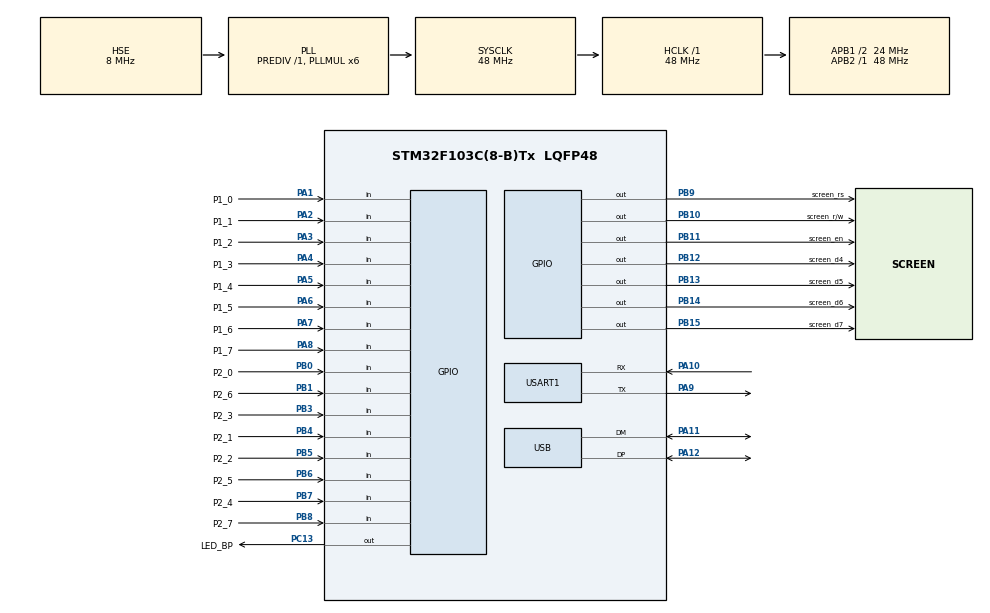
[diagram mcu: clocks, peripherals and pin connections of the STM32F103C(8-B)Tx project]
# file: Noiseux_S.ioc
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Mcu.Family=STM32F1
Mcu.Name=STM32F103C(8-B)Tx
Mcu.Package=LQFP48
NVIC.PriorityGroup=NVIC_PRIORITYGROUP_4
NVIC.USB_LP_CAN1_RX0_IRQn=true\:0\:0\:false\:false\:true\:false\:true\:true
PA1.GPIO_Label=P1_0
PA1.Signal=GPIO_Input
PA10.Mode=Asynchronous
PA10.Signal=USART1_RX
PA11.Mode=Device
PA11.Signal=USB_DM
PA12.Mode=Device
PA12.Signal=USB_DP
PA2.GPIO_Label=P1_1
PA2.Signal=GPIO_Input
PA3.GPIO_Label=P1_2
PA3.Signal=GPIO_Input
PA4.GPIO_Label=P1_3
PA4.Signal=GPIO_Input
PA5.GPIO_Label=P1_4
PA5.Signal=GPIO_Input
PA6.GPIO_Label=P1_5
PA6.Signal=GPIO_Input
PA7.GPIO_Label=P1_6
PA7.Signal=GPIO_Input
PA8.GPIO_Label=P1_7
PA8.Signal=GPIO_Input
PA9.Mode=Asynchronous
PA9.Signal=USART1_TX
PB0.GPIO_Label=P2_0
PB0.Signal=GPIO_Input
PB1.GPIO_Label=P2_6
PB1.Signal=GPIO_Input
PB10.GPIO_Label=screen_r/w
PB10.Signal=GPIO_Output
PB11.GPIO_Label=screen_en
PB11.Signal=GPIO_Output
PB12.GPIO_Label=screen_d4
PB12.Signal=GPIO_Output
PB13.GPIO_Label=screen_d5
PB13.Signal=GPIO_Output
PB14.GPIO_Label=screen_d6
PB14.Signal=GPIO_Output
PB15.GPIO_Label=screen_d7
PB15.Signal=GPIO_Output
PB3.GPIO_Label=P2_3
PB3.Signal=GPIO_Input
PB4.GPIO_Label=P2_1
PB4.Signal=GPIO_Input
PB5.GPIO_Label=P2_2
PB5.Signal=GPIO_Input
PB6.GPIO_Label=P2_5
PB6.Signal=GPIO_Input
PB7.GPIO_Label=P2_4
PB7.Signal=GPIO_Input
PB8.GPIO_Label=P2_7
PB8.Signal=GPIO_Input
PB9.GPIO_Label=screen_rs
PB9.Signal=GPIO_Output
PC13-TAMPER-RTC.GPIO_Label=LED_BP
PC13-TAMPER-RTC.Signal=GPIO_Output
PD0-OSC_IN.Mode=HSE-External-Oscillator
PD0-OSC_IN.Signal=RCC_OSC_IN
PD1-OSC_OUT.Mode=HSE-External-Oscillator
PD1-OSC_OUT.Signal=RCC_OSC_OUT
ProjectManager.HeapSize=0x200
ProjectManager.StackSize=0x400
ProjectManager.TargetToolchain=STM32CubeIDE
RCC.AHBFreq_Value=48000000
RCC.APB1CLKDivider=RCC_HCLK_DIV2
RCC.APB1Freq_Value=24000000
RCC.APB1TimFreq_Value=48000000
RCC.APB2Freq_Value=48000000
RCC.APB2TimFreq_Value=48000000
RCC.HCLKFreq_Value=48000000
RCC.PLLMUL=RCC_PLL_MUL6
RCC.SYSCLKFreq_VALUE=48000000
RCC.SYSCLKSource=RCC_SYSCLKSOURCE_PLLCLK
RCC.USBFreq_Value=48000000
USART1.VirtualMode=VM_ASYNC
USB_DEVICE.CLASS_NAME_FS=CDC
USB_DEVICE.VirtualMode=Cdc
USB_DEVICE.VirtualModeFS=Cdc_FS
VP_SYS_VS_ND.Mode=No_Debug
VP_USB_DEVICE_VS_USB_DEVICE_CDC_FS.Mode=CDC_FS
board=custom

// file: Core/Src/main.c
/* USER CODE BEGIN Header */
/**
  ******************************************************************************
  * @file           : main.c
  * @brief          : Main program body
  ******************************************************************************
  * @attention
  *
  * Copyright (c) 2025 STMicroelectronics.
  * All rights reserved.
  *
  * This software is licensed under terms that can be found in the LICENSE file
  * in the root directory of this software component.
  * If no LICENSE file comes with this software, it is provided AS-IS.
  *
  ******************************************************************************
  */
/* USER CODE END Header */
#include "main.h"
#include "usb_device.h"

/* USER CODE BEGIN Includes */
#include "usbd_cdc_if.h"
#include "ecran.h"

/* USER CODE END Includes */

UART_HandleTypeDef huart1;

void SystemClock_Config(void);
static void MX_GPIO_Init(void);
static void MX_USART1_UART_Init(void);

int main(void)
{

  /* MCU Configuration--------------------------------------------------------*/

  /* Reset of all peripherals, Initializes the Flash interface and the Systick. */
  HAL_Init();

  /* Configure the system clock */
  SystemClock_Config();

  /* Initialize all configured peripherals */
  MX_GPIO_Init();
  MX_USART1_UART_Init();
  MX_USB_DEVICE_Init();
  /* USER CODE BEGIN 2 */
  LCD_Init();

  /* USER CODE END 2 */

  /* Infinite loop */
  /* USER CODE BEGIN WHILE */
  while (1)
  {
	  LCD_Char(0x00);
    /* USER CODE END WHILE */

  }
}

void SystemClock_Config(void)
{
  RCC_OscInitTypeDef RCC_OscInitStruct = {0};
  RCC_ClkInitTypeDef RCC_ClkInitStruct = {0};
  RCC_PeriphCLKInitTypeDef PeriphClkInit = {0};

  /** Initializes the RCC Oscillators according to the specified parameters
  * in the RCC_OscInitTypeDef structure.
  */
  RCC_OscInitStruct.OscillatorType = RCC_OSCILLATORTYPE_HSE;
  RCC_OscInitStruct.HSEState = RCC_HSE_ON;
  RCC_OscInitStruct.HSEPredivValue = RCC_HSE_PREDIV_DIV1;
  RCC_OscInitStruct.HSIState = RCC_HSI_ON;
  RCC_OscInitStruct.PLL.PLLState = RCC_PLL_ON;
  RCC_OscInitStruct.PLL.PLLSource = RCC_PLLSOURCE_HSE;
  RCC_OscInitStruct.PLL.PLLMUL = RCC_PLL_MUL6;
  if (HAL_RCC_OscConfig(&RCC_OscInitStruct) != HAL_OK)
  {
    Error_Handler();
  }

  /** Initializes the CPU, AHB and APB buses clocks
  */
  RCC_ClkInitStruct.ClockType = RCC_CLOCKTYPE_HCLK|RCC_CLOCKTYPE_SYSCLK
                              |RCC_CLOCKTYPE_PCLK1|RCC_CLOCKTYPE_PCLK2;
  RCC_ClkInitStruct.SYSCLKSource = RCC_SYSCLKSOURCE_PLLCLK;
  RCC_ClkInitStruct.AHBCLKDivider = RCC_SYSCLK_DIV1;
  RCC_ClkInitStruct.APB1CLKDivider = RCC_HCLK_DIV2;
  RCC_ClkInitStruct.APB2CLKDivider = RCC_HCLK_DIV1;

  if (HAL_RCC_ClockConfig(&RCC_ClkInitStruct, FLASH_LATENCY_1) != HAL_OK)
  {
    Error_Handler();
  }
  PeriphClkInit.PeriphClockSelection = RCC_PERIPHCLK_USB;
  PeriphClkInit.UsbClockSelection = RCC_USBCLKSOURCE_PLL;
  if (HAL_RCCEx_PeriphCLKConfig(&PeriphClkInit) != HAL_OK)
  {
    Error_Handler();
  }
}

static void MX_USART1_UART_Init(void)
{

  huart1.Instance = USART1;
  huart1.Init.BaudRate = 115200;
  huart1.Init.WordLength = UART_WORDLENGTH_8B;
  huart1.Init.StopBits = UART_STOPBITS_1;
  huart1.Init.Parity = UART_PARITY_NONE;
  huart1.Init.Mode = UART_MODE_TX_RX;
  huart1.Init.HwFlowCtl = UART_HWCONTROL_NONE;
  huart1.Init.OverSampling = UART_OVERSAMPLING_16;
  if (HAL_UART_Init(&huart1) != HAL_OK)
  {
    Error_Handler();
  }

}

static void MX_GPIO_Init(void)
{
  GPIO_InitTypeDef GPIO_InitStruct = {0};

  /* GPIO Ports Clock Enable */
  __HAL_RCC_GPIOC_CLK_ENABLE();
  __HAL_RCC_GPIOD_CLK_ENABLE();
  __HAL_RCC_GPIOA_CLK_ENABLE();
  __HAL_RCC_GPIOB_CLK_ENABLE();

  /*Configure GPIO pin Output Level */
  HAL_GPIO_WritePin(LED_BP_GPIO_Port, LED_BP_Pin, GPIO_PIN_RESET);

  /*Configure GPIO pin Output Level */
  HAL_GPIO_WritePin(GPIOB, screen_r_w_Pin|screen_en_Pin|screen_d4_Pin|screen_d5_Pin
                          |screen_d6_Pin|screen_d7_Pin|screen_rs_Pin, GPIO_PIN_RESET);

  /*Configure GPIO pin : LED_BP_Pin */
  GPIO_InitStruct.Pin = LED_BP_Pin;
  GPIO_InitStruct.Mode = GPIO_MODE_OUTPUT_PP;
  GPIO_InitStruct.Pull = GPIO_NOPULL;
  GPIO_InitStruct.Speed = GPIO_SPEED_FREQ_LOW;
  HAL_GPIO_Init(LED_BP_GPIO_Port, &GPIO_InitStruct);

  /*Configure GPIO pins : P1_0_Pin P1_1_Pin P1_2_Pin P1_3_Pin
                           P1_4_Pin P1_5_Pin P1_6_Pin P1_7_Pin */
  GPIO_InitStruct.Pin = P1_0_Pin|P1_1_Pin|P1_2_Pin|P1_3_Pin
                          |P1_4_Pin|P1_5_Pin|P1_6_Pin|P1_7_Pin;
  GPIO_InitStruct.Mode = GPIO_MODE_INPUT;
  GPIO_InitStruct.Pull = GPIO_NOPULL;
  HAL_GPIO_Init(GPIOA, &GPIO_InitStruct);

  /*Configure GPIO pins : P2_0_Pin P2_6_Pin P2_3_Pin P2_1_Pin
                           P2_2_Pin P2_5_Pin P2_4_Pin P2_7_Pin */
  GPIO_InitStruct.Pin = P2_0_Pin|P2_6_Pin|P2_3_Pin|P2_1_Pin
                          |P2_2_Pin|P2_5_Pin|P2_4_Pin|P2_7_Pin;
  GPIO_InitStruct.Mode = GPIO_MODE_INPUT;
  GPIO_InitStruct.Pull = GPIO_NOPULL;
  HAL_GPIO_Init(GPIOB, &GPIO_InitStruct);

  /*Configure GPIO pins : screen_r_w_Pin screen_en_Pin screen_d4_Pin screen_d5_Pin
                           screen_d6_Pin screen_d7_Pin screen_rs_Pin */
  GPIO_InitStruct.Pin = screen_r_w_Pin|screen_en_Pin|screen_d4_Pin|screen_d5_Pin
                          |screen_d6_Pin|screen_d7_Pin|screen_rs_Pin;
  GPIO_InitStruct.Mode = GPIO_MODE_OUTPUT_PP;
  GPIO_InitStruct.Pull = GPIO_NOPULL;
  GPIO_InitStruct.Speed = GPIO_SPEED_FREQ_LOW;
  HAL_GPIO_Init(GPIOB, &GPIO_InitStruct);

}

void Error_Handler(void)
{
  __disable_irq();
  while (1)
  {
  }
}
